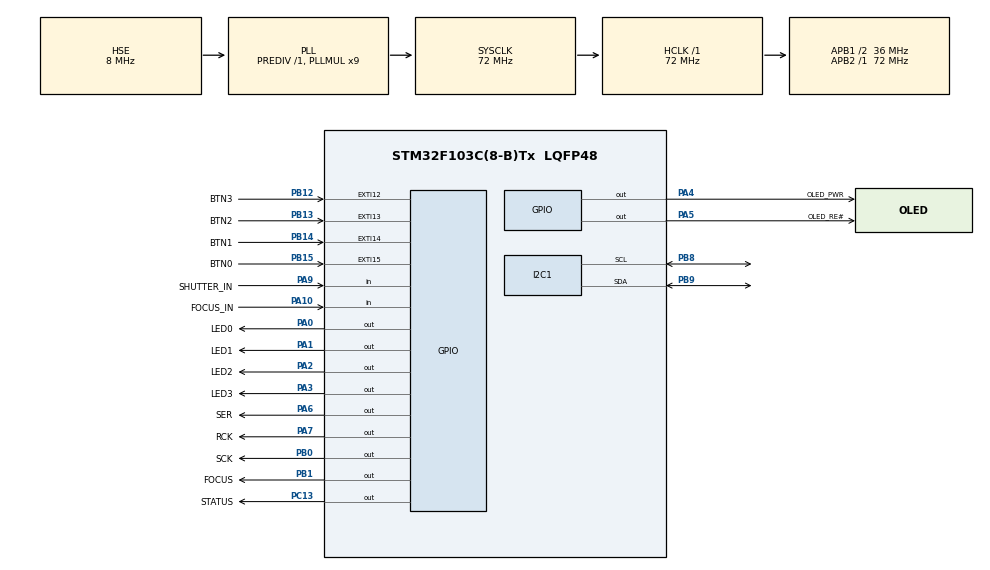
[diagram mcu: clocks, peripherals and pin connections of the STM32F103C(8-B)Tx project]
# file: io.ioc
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I2C1.I2C_Mode=I2C_Fast
Mcu.Family=STM32F1
Mcu.Name=STM32F103C(8-B)Tx
Mcu.Package=LQFP48
NVIC.EXTI15_10_IRQn=true\:0\:0\:false\:false\:true\:true\:true\:true
NVIC.PriorityGroup=NVIC_PRIORITYGROUP_4
PA0-WKUP.GPIO_Label=LED0
PA0-WKUP.PinState=GPIO_PIN_SET
PA0-WKUP.Signal=GPIO_Output
PA1.GPIO_Label=LED1
PA1.PinState=GPIO_PIN_SET
PA1.Signal=GPIO_Output
PA10.GPIO_Label=FOCUS_IN
PA10.Signal=GPIO_Input
PA13.Mode=Serial_Wire
PA13.Signal=SYS_JTMS-SWDIO
PA14.Mode=Serial_Wire
PA14.Signal=SYS_JTCK-SWCLK
PA2.GPIO_Label=LED2
PA2.PinState=GPIO_PIN_SET
PA2.Signal=GPIO_Output
PA3.GPIO_Label=LED3
PA3.PinState=GPIO_PIN_SET
PA3.Signal=GPIO_Output
PA4.GPIO_Label=OLED_PWR
PA4.PinState=GPIO_PIN_SET
PA4.Signal=GPIO_Output
PA5.GPIO_Label=OLED_RE\#
PA5.Signal=GPIO_Output
PA6.GPIO_Label=SER
PA6.GPIO_Speed=GPIO_SPEED_FREQ_HIGH
PA6.Signal=GPIO_Output
PA7.GPIO_Label=RCK
PA7.GPIO_Speed=GPIO_SPEED_FREQ_HIGH
PA7.Signal=GPIO_Output
PA9.GPIO_Label=SHUTTER_IN
PA9.Signal=GPIO_Input
PB0.GPIO_Label=SCK
PB0.GPIO_Speed=GPIO_SPEED_FREQ_HIGH
PB0.PinState=GPIO_PIN_RESET
PB0.Signal=GPIO_Output
PB1.GPIO_Label=FOCUS
PB1.GPIO_ModeDefaultOutputPP=GPIO_MODE_OUTPUT_OD
PB1.GPIO_PuPd=GPIO_NOPULL
PB1.PinState=GPIO_PIN_SET
PB1.Signal=GPIO_Output
PB12.GPIO_Label=BTN3
PB12.GPIO_ModeDefaultEXTI=GPIO_MODE_IT_RISING_FALLING
PB12.GPIO_PuPd=GPIO_PULLUP
PB12.Signal=GPXTI12
PB13.GPIO_Label=BTN2
PB13.GPIO_ModeDefaultEXTI=GPIO_MODE_IT_RISING_FALLING
PB13.GPIO_PuPd=GPIO_PULLUP
PB13.Signal=GPXTI13
PB14.GPIO_Label=BTN1
PB14.GPIO_ModeDefaultEXTI=GPIO_MODE_IT_RISING_FALLING
PB14.GPIO_PuPd=GPIO_PULLUP
PB14.Signal=GPXTI14
PB15.GPIO_Label=BTN0
PB15.GPIO_ModeDefaultEXTI=GPIO_MODE_IT_RISING_FALLING
PB15.GPIO_PuPd=GPIO_PULLUP
PB15.Signal=GPXTI15
PB8.Mode=I2C
PB8.Signal=I2C1_SCL
PB9.Mode=I2C
PB9.Signal=I2C1_SDA
PC13-TAMPER-RTC.GPIO_Label=STATUS
PC13-TAMPER-RTC.Signal=GPIO_Output
PC14-OSC32_IN.Mode=LSE-External-Oscillator
PC14-OSC32_IN.Signal=RCC_OSC32_IN
PC15-OSC32_OUT.Mode=LSE-External-Oscillator
PC15-OSC32_OUT.Signal=RCC_OSC32_OUT
PD0-OSC_IN.Mode=HSE-External-Oscillator
PD0-OSC_IN.Signal=RCC_OSC_IN
PD1-OSC_OUT.Mode=HSE-External-Oscillator
PD1-OSC_OUT.Signal=RCC_OSC_OUT
ProjectManager.HeapSize=0x200
ProjectManager.StackSize=0x400
ProjectManager.TargetToolchain=Makefile
RCC.AHBFreq_Value=72000000
RCC.APB1CLKDivider=RCC_HCLK_DIV2
RCC.APB1Freq_Value=36000000
RCC.APB1TimFreq_Value=72000000
RCC.APB2Freq_Value=72000000
RCC.APB2TimFreq_Value=72000000
RCC.HCLKFreq_Value=72000000
RCC.PLLMUL=RCC_PLL_MUL9
RCC.PLLSourceVirtual=RCC_PLLSOURCE_HSE
RCC.SYSCLKFreq_VALUE=72000000
RCC.SYSCLKSource=RCC_SYSCLKSOURCE_PLLCLK
RCC.USBFreq_Value=72000000
board=custom

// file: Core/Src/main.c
/* USER CODE BEGIN Header */
/**
  ******************************************************************************
  * @file           : main.c
  * @brief          : Main program body
  ******************************************************************************
  * @attention
  *
  * Copyright (c) 2022 STMicroelectronics.
  * All rights reserved.
  *
  * This software is licensed under terms that can be found in the LICENSE file
  * in the root directory of this software component.
  * If no LICENSE file comes with this software, it is provided AS-IS.
  *
  ******************************************************************************
  */
/* USER CODE END Header */
#include "main.h"

I2C_HandleTypeDef hi2c1;

void SystemClock_Config(void);
static void MX_GPIO_Init(void);
static void MX_I2C1_Init(void);
/* USER CODE BEGIN PFP */
void main_loop(void);
/* USER CODE END PFP */

int main(void)
{

  /* MCU Configuration--------------------------------------------------------*/

  /* Reset of all peripherals, Initializes the Flash interface and the Systick. */
  HAL_Init();

  /* Configure the system clock */
  SystemClock_Config();

  /* Initialize all configured peripherals */
  MX_GPIO_Init();
  MX_I2C1_Init();

  /* Infinite loop */
  /* USER CODE BEGIN WHILE */
  main_loop();

  while (1)
  {
    /* USER CODE END WHILE */

  }
}

void SystemClock_Config(void)
{
  RCC_OscInitTypeDef RCC_OscInitStruct = {0};
  RCC_ClkInitTypeDef RCC_ClkInitStruct = {0};

  /** Initializes the RCC Oscillators according to the specified parameters
  * in the RCC_OscInitTypeDef structure.
  */
  RCC_OscInitStruct.OscillatorType = RCC_OSCILLATORTYPE_HSE;
  RCC_OscInitStruct.HSEState = RCC_HSE_ON;
  RCC_OscInitStruct.HSEPredivValue = RCC_HSE_PREDIV_DIV1;
  RCC_OscInitStruct.HSIState = RCC_HSI_ON;
  RCC_OscInitStruct.PLL.PLLState = RCC_PLL_ON;
  RCC_OscInitStruct.PLL.PLLSource = RCC_PLLSOURCE_HSE;
  RCC_OscInitStruct.PLL.PLLMUL = RCC_PLL_MUL9;
  if (HAL_RCC_OscConfig(&RCC_OscInitStruct) != HAL_OK)
  {
    Error_Handler();
  }

  /** Initializes the CPU, AHB and APB buses clocks
  */
  RCC_ClkInitStruct.ClockType = RCC_CLOCKTYPE_HCLK|RCC_CLOCKTYPE_SYSCLK
                              |RCC_CLOCKTYPE_PCLK1|RCC_CLOCKTYPE_PCLK2;
  RCC_ClkInitStruct.SYSCLKSource = RCC_SYSCLKSOURCE_PLLCLK;
  RCC_ClkInitStruct.AHBCLKDivider = RCC_SYSCLK_DIV1;
  RCC_ClkInitStruct.APB1CLKDivider = RCC_HCLK_DIV2;
  RCC_ClkInitStruct.APB2CLKDivider = RCC_HCLK_DIV1;

  if (HAL_RCC_ClockConfig(&RCC_ClkInitStruct, FLASH_LATENCY_2) != HAL_OK)
  {
    Error_Handler();
  }
}

static void MX_I2C1_Init(void)
{

  hi2c1.Instance = I2C1;
  hi2c1.Init.ClockSpeed = 400000;
  hi2c1.Init.DutyCycle = I2C_DUTYCYCLE_2;
  hi2c1.Init.OwnAddress1 = 0;
  hi2c1.Init.AddressingMode = I2C_ADDRESSINGMODE_7BIT;
  hi2c1.Init.DualAddressMode = I2C_DUALADDRESS_DISABLE;
  hi2c1.Init.OwnAddress2 = 0;
  hi2c1.Init.GeneralCallMode = I2C_GENERALCALL_DISABLE;
  hi2c1.Init.NoStretchMode = I2C_NOSTRETCH_DISABLE;
  if (HAL_I2C_Init(&hi2c1) != HAL_OK)
  {
    Error_Handler();
  }

}

static void MX_GPIO_Init(void)
{
  GPIO_InitTypeDef GPIO_InitStruct = {0};

  /* GPIO Ports Clock Enable */
  __HAL_RCC_GPIOC_CLK_ENABLE();
  __HAL_RCC_GPIOD_CLK_ENABLE();
  __HAL_RCC_GPIOA_CLK_ENABLE();
  __HAL_RCC_GPIOB_CLK_ENABLE();

  /*Configure GPIO pin Output Level */
  HAL_GPIO_WritePin(STATUS_GPIO_Port, STATUS_Pin, GPIO_PIN_RESET);

  /*Configure GPIO pin Output Level */
  HAL_GPIO_WritePin(GPIOA, LED0_Pin|LED1_Pin|LED2_Pin|LED3_Pin
                          |OLED_PWR_Pin, GPIO_PIN_SET);

  /*Configure GPIO pin Output Level */
  HAL_GPIO_WritePin(GPIOA, OLED_RE__Pin|SER_Pin|RCK_Pin, GPIO_PIN_RESET);

  /*Configure GPIO pin Output Level */
  HAL_GPIO_WritePin(SCK_GPIO_Port, SCK_Pin, GPIO_PIN_RESET);

  /*Configure GPIO pin Output Level */
  HAL_GPIO_WritePin(FOCUS_GPIO_Port, FOCUS_Pin, GPIO_PIN_SET);

  /*Configure GPIO pin : STATUS_Pin */
  GPIO_InitStruct.Pin = STATUS_Pin;
  GPIO_InitStruct.Mode = GPIO_MODE_OUTPUT_PP;
  GPIO_InitStruct.Pull = GPIO_NOPULL;
  GPIO_InitStruct.Speed = GPIO_SPEED_FREQ_LOW;
  HAL_GPIO_Init(STATUS_GPIO_Port, &GPIO_InitStruct);

  /*Configure GPIO pins : LED0_Pin LED1_Pin LED2_Pin LED3_Pin
                           OLED_PWR_Pin OLED_RE__Pin */
  GPIO_InitStruct.Pin = LED0_Pin|LED1_Pin|LED2_Pin|LED3_Pin
                          |OLED_PWR_Pin|OLED_RE__Pin;
  GPIO_InitStruct.Mode = GPIO_MODE_OUTPUT_PP;
  GPIO_InitStruct.Pull = GPIO_NOPULL;
  GPIO_InitStruct.Speed = GPIO_SPEED_FREQ_LOW;
  HAL_GPIO_Init(GPIOA, &GPIO_InitStruct);

  /*Configure GPIO pins : SER_Pin RCK_Pin */
  GPIO_InitStruct.Pin = SER_Pin|RCK_Pin;
  GPIO_InitStruct.Mode = GPIO_MODE_OUTPUT_PP;
  GPIO_InitStruct.Pull = GPIO_NOPULL;
  GPIO_InitStruct.Speed = GPIO_SPEED_FREQ_HIGH;
  HAL_GPIO_Init(GPIOA, &GPIO_InitStruct);

  /*Configure GPIO pin : SCK_Pin */
  GPIO_InitStruct.Pin = SCK_Pin;
  GPIO_InitStruct.Mode = GPIO_MODE_OUTPUT_PP;
  GPIO_InitStruct.Pull = GPIO_NOPULL;
  GPIO_InitStruct.Speed = GPIO_SPEED_FREQ_HIGH;
  HAL_GPIO_Init(SCK_GPIO_Port, &GPIO_InitStruct);

  /*Configure GPIO pin : FOCUS_Pin */
  GPIO_InitStruct.Pin = FOCUS_Pin;
  GPIO_InitStruct.Mode = GPIO_MODE_OUTPUT_OD;
  GPIO_InitStruct.Pull = GPIO_NOPULL;
  GPIO_InitStruct.Speed = GPIO_SPEED_FREQ_LOW;
  HAL_GPIO_Init(FOCUS_GPIO_Port, &GPIO_InitStruct);

  /*Configure GPIO pins : PB2 PB10 PB11 PB3
                           PB4 PB5 PB6 PB7 */
  GPIO_InitStruct.Pin = GPIO_PIN_2|GPIO_PIN_10|GPIO_PIN_11|GPIO_PIN_3
                          |GPIO_PIN_4|GPIO_PIN_5|GPIO_PIN_6|GPIO_PIN_7;
  GPIO_InitStruct.Mode = GPIO_MODE_ANALOG;
  HAL_GPIO_Init(GPIOB, &GPIO_InitStruct);

  /*Configure GPIO pins : BTN3_Pin BTN2_Pin BTN1_Pin BTN0_Pin */
  GPIO_InitStruct.Pin = BTN3_Pin|BTN2_Pin|BTN1_Pin|BTN0_Pin;
  GPIO_InitStruct.Mode = GPIO_MODE_IT_RISING_FALLING;
  GPIO_InitStruct.Pull = GPIO_PULLUP;
  HAL_GPIO_Init(GPIOB, &GPIO_InitStruct);

  /*Configure GPIO pins : PA8 PA11 PA12 PA15 */
  GPIO_InitStruct.Pin = GPIO_PIN_8|GPIO_PIN_11|GPIO_PIN_12|GPIO_PIN_15;
  GPIO_InitStruct.Mode = GPIO_MODE_ANALOG;
  HAL_GPIO_Init(GPIOA, &GPIO_InitStruct);

  /*Configure GPIO pins : SHUTTER_IN_Pin FOCUS_IN_Pin */
  GPIO_InitStruct.Pin = SHUTTER_IN_Pin|FOCUS_IN_Pin;
  GPIO_InitStruct.Mode = GPIO_MODE_INPUT;
  GPIO_InitStruct.Pull = GPIO_NOPULL;
  HAL_GPIO_Init(GPIOA, &GPIO_InitStruct);

  /* EXTI interrupt init*/
  HAL_NVIC_SetPriority(EXTI15_10_IRQn, 0, 0);
  HAL_NVIC_EnableIRQ(EXTI15_10_IRQn);

}

void Error_Handler(void)
{
  __disable_irq();
  while (1)
  {
  }
}
